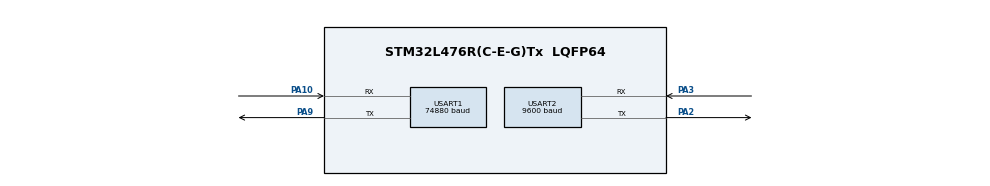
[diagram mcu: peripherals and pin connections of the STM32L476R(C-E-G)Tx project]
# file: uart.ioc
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Mcu.Family=STM32L4
Mcu.Name=STM32L476R(C-E-G)Tx
Mcu.Package=LQFP64
NVIC.PriorityGroup=NVIC_PRIORITYGROUP_4
PA10.Mode=Asynchronous
PA10.Signal=USART1_RX
PA2.Mode=Asynchronous
PA2.Signal=USART2_TX
PA3.Mode=Asynchronous
PA3.Signal=USART2_RX
PA9.Mode=Asynchronous
PA9.Signal=USART1_TX
ProjectManager.HeapSize=0x200
ProjectManager.StackSize=0x400
ProjectManager.TargetToolchain=MDK-ARM V5.32
RCC.HSE_VALUE=8000000
RCC.HSI_VALUE=16000000
RCC.LSE_VALUE=32768
RCC.MSI_VALUE=4000000
RCC.VCOOutputFreq_Value=32000000
USART1.BaudRate=74880
USART1.VirtualMode-Asynchronous=VM_ASYNC
USART2.BaudRate=9600
USART2.VirtualMode-Asynchronous=VM_ASYNC
board=custom

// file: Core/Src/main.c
/* USER CODE BEGIN Header */
/**
  ******************************************************************************
  * @file           : main.c
  * @brief          : Main program body
  ******************************************************************************
  * @attention
  *
  * <h2><center>&copy; Copyright (c) 2022 STMicroelectronics.
  * All rights reserved.</center></h2>
  *
  * This software component is licensed by ST under BSD 3-Clause license,
  * the "License"; You may not use this file except in compliance with the
  * License. You may obtain a copy of the License at:
  *                        opensource.org/licenses/BSD-3-Clause
  *
  ******************************************************************************
  */
/* USER CODE END Header */
#include "main.h"

/* USER CODE BEGIN Includes */
#include <stdio.h>
#include <string.h>
/* USER CODE END Includes */

UART_HandleTypeDef huart1;
UART_HandleTypeDef huart2;

void SystemClock_Config(void);
static void MX_GPIO_Init(void);
static void MX_USART1_UART_Init(void);
static void MX_USART2_UART_Init(void);

/* USER CODE BEGIN 0 */
#ifdef __GNUC__
  /* With GCC, small printf (option LD Linker->Libraries->Small printf
     set to 'Yes') calls __io_putchar() */
  #define PUTCHAR_PROTOTYPE int __io_putchar(int ch)
#else
  #define PUTCHAR_PROTOTYPE int fputc(int ch, FILE *f)
#endif /* __GNUC__ */

PUTCHAR_PROTOTYPE
{
  /* Place your implementation of fputc here */
  /* e.g. write a character to the EVAL_COM1 and Loop until the end of transmission */
  HAL_UART_Transmit(&huart2, (uint8_t *)&ch, 1, HAL_MAX_DELAY);

  return ch;
}
/* USER CODE END 0 */

int main(void)
{

  /* MCU Configuration--------------------------------------------------------*/

  /* Reset of all peripherals, Initializes the Flash interface and the Systick. */
  HAL_Init();

  /* Configure the system clock */
  SystemClock_Config();

  /* Initialize all configured peripherals */
  MX_GPIO_Init();
  MX_USART1_UART_Init();
  MX_USART2_UART_Init();
  /* USER CODE BEGIN 2 */
  uint8_t data[6] = "hello";
  /* USER CODE END 2 */

  /* Infinite loop */
  /* USER CODE BEGIN WHILE */
  while (1)
  {
    HAL_UART_Transmit(&huart1, data, strlen((char*)data), HAL_MAX_DELAY);
    HAL_Delay(2000);
    /* USER CODE END WHILE */

  }
}

void SystemClock_Config(void)
{
  RCC_OscInitTypeDef RCC_OscInitStruct = {0};
  RCC_ClkInitTypeDef RCC_ClkInitStruct = {0};

  /** Configure the main internal regulator output voltage
  */
  if (HAL_PWREx_ControlVoltageScaling(PWR_REGULATOR_VOLTAGE_SCALE1) != HAL_OK)
  {
    Error_Handler();
  }
  /** Initializes the RCC Oscillators according to the specified parameters
  * in the RCC_OscInitTypeDef structure.
  */
  RCC_OscInitStruct.OscillatorType = RCC_OSCILLATORTYPE_MSI;
  RCC_OscInitStruct.MSIState = RCC_MSI_ON;
  RCC_OscInitStruct.MSICalibrationValue = 0;
  RCC_OscInitStruct.MSIClockRange = RCC_MSIRANGE_6;
  RCC_OscInitStruct.PLL.PLLState = RCC_PLL_NONE;
  if (HAL_RCC_OscConfig(&RCC_OscInitStruct) != HAL_OK)
  {
    Error_Handler();
  }
  /** Initializes the CPU, AHB and APB buses clocks
  */
  RCC_ClkInitStruct.ClockType = RCC_CLOCKTYPE_HCLK|RCC_CLOCKTYPE_SYSCLK
                              |RCC_CLOCKTYPE_PCLK1|RCC_CLOCKTYPE_PCLK2;
  RCC_ClkInitStruct.SYSCLKSource = RCC_SYSCLKSOURCE_MSI;
  RCC_ClkInitStruct.AHBCLKDivider = RCC_SYSCLK_DIV1;
  RCC_ClkInitStruct.APB1CLKDivider = RCC_HCLK_DIV1;
  RCC_ClkInitStruct.APB2CLKDivider = RCC_HCLK_DIV1;

  if (HAL_RCC_ClockConfig(&RCC_ClkInitStruct, FLASH_LATENCY_0) != HAL_OK)
  {
    Error_Handler();
  }
}

static void MX_USART1_UART_Init(void)
{

  huart1.Instance = USART1;
  huart1.Init.BaudRate = 74880;
  huart1.Init.WordLength = UART_WORDLENGTH_8B;
  huart1.Init.StopBits = UART_STOPBITS_1;
  huart1.Init.Parity = UART_PARITY_NONE;
  huart1.Init.Mode = UART_MODE_TX_RX;
  huart1.Init.HwFlowCtl = UART_HWCONTROL_NONE;
  huart1.Init.OverSampling = UART_OVERSAMPLING_16;
  huart1.Init.OneBitSampling = UART_ONE_BIT_SAMPLE_DISABLE;
  huart1.AdvancedInit.AdvFeatureInit = UART_ADVFEATURE_NO_INIT;
  if (HAL_UART_Init(&huart1) != HAL_OK)
  {
    Error_Handler();
  }

}

static void MX_USART2_UART_Init(void)
{

  huart2.Instance = USART2;
  huart2.Init.BaudRate = 9600;
  huart2.Init.WordLength = UART_WORDLENGTH_8B;
  huart2.Init.StopBits = UART_STOPBITS_1;
  huart2.Init.Parity = UART_PARITY_NONE;
  huart2.Init.Mode = UART_MODE_TX_RX;
  huart2.Init.HwFlowCtl = UART_HWCONTROL_NONE;
  huart2.Init.OverSampling = UART_OVERSAMPLING_16;
  huart2.Init.OneBitSampling = UART_ONE_BIT_SAMPLE_DISABLE;
  huart2.AdvancedInit.AdvFeatureInit = UART_ADVFEATURE_NO_INIT;
  if (HAL_UART_Init(&huart2) != HAL_OK)
  {
    Error_Handler();
  }

}

static void MX_GPIO_Init(void)
{

  /* GPIO Ports Clock Enable */
  __HAL_RCC_GPIOA_CLK_ENABLE();

}

void Error_Handler(void)
{
  __disable_irq();
  while (1)
  {
  }
}

/************************ (C) COPYRIGHT STMicroelectronics *****END OF FILE****/
